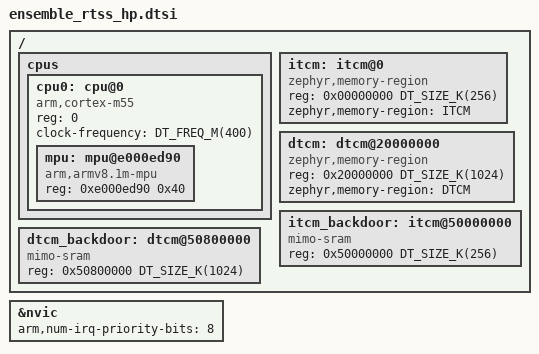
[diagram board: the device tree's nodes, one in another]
/*
 * Copyright (c) 2025 Alif Semiconductor
 *
 * SPDX-License-Identifier: Apache-2.0
 */

#include <arm/armv8.1-m.dtsi>
#include <freq.h>

/ {
	cpus {
		#address-cells = <1>;
		#size-cells = <0>;

		cpu0: cpu@0 {
			compatible = "arm,cortex-m55";
			reg = <0>;
			device_type = "cpu";
			clock-frequency = <DT_FREQ_M(400)>;
			#address-cells = <1>;
			#size-cells = <1>;

			mpu: mpu@e000ed90 {
				compatible = "arm,armv8.1m-mpu";
				reg = <0xe000ed90 0x40>;
			};
		};
	};

	itcm: itcm@0 {
		compatible = "zephyr,memory-region", "arm,itcm";
		reg = <0x00000000 DT_SIZE_K(256)>;
		zephyr,memory-region = "ITCM";
	};

	dtcm: dtcm@20000000 {
		compatible = "zephyr,memory-region", "arm,dtcm";
		reg = <0x20000000 DT_SIZE_K(1024)>;
		zephyr,memory-region = "DTCM";
	};

	/*
	 * Copies of ITCM and DTCM accessible from other cores, as well
	 * as from bus masters like DMA and JPEG.
	 */
	itcm_backdoor: itcm@50000000 {
		compatible = "mimo-sram";
		reg = <0x50000000 DT_SIZE_K(256)>;
	};

	dtcm_backdoor: dtcm@50800000 {
		compatible = "mimo-sram";
		reg = <0x50800000 DT_SIZE_K(1024)>;
	};
};

&nvic {
	arm,num-irq-priority-bits = <8>;
};
